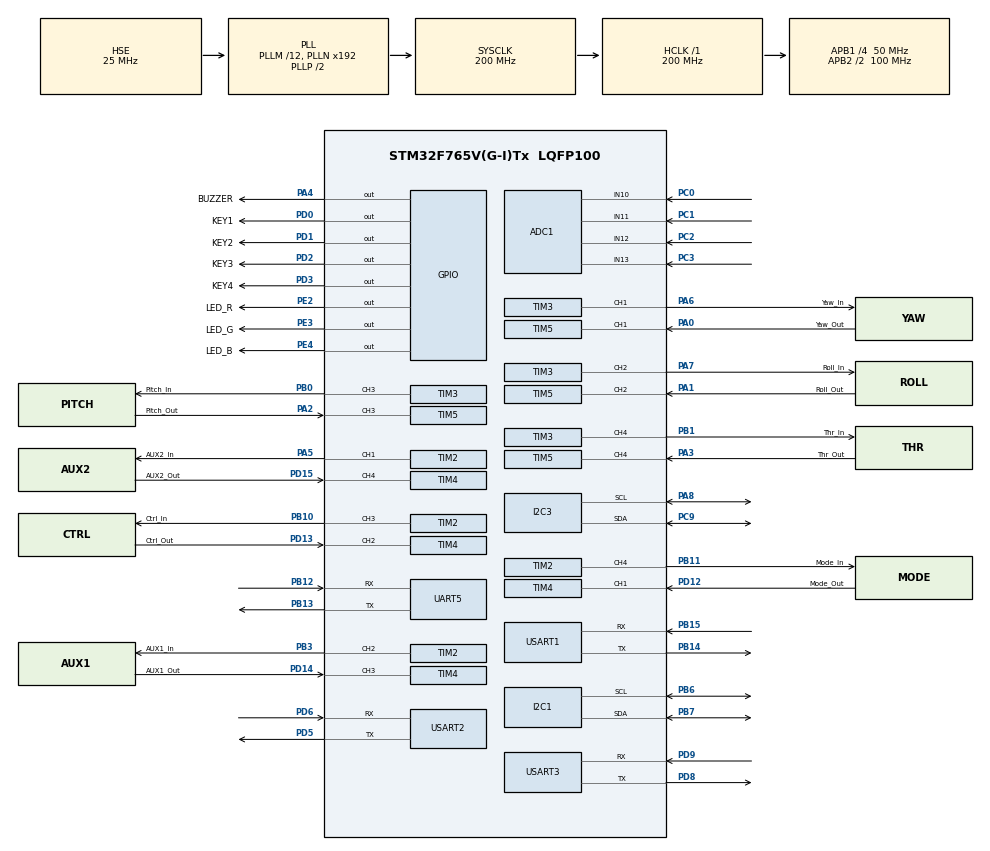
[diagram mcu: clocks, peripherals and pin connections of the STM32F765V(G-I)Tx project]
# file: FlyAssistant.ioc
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ADC1.Channel-1\#ChannelRegularConversion=ADC_CHANNEL_10
ADC1.NbrOfConversionFlag=1
ADC1.Rank-1\#ChannelRegularConversion=1
ADC1.SamplingTime-1\#ChannelRegularConversion=ADC_SAMPLETIME_3CYCLES
ADC1.master=1
CORTEX_M7.default_mode_Activation=1
I2C1.Timing=0x00C0EAFF
I2C3.Timing=0x00C0EAFF
Mcu.Family=STM32F7
Mcu.Name=STM32F765V(G-I)Tx
Mcu.Package=LQFP100
NVIC.PriorityGroup=NVIC_PRIORITYGROUP_4
NVIC.TIM2_IRQn=true\:0\:0\:false\:false\:true\:true\:true\:true
NVIC.TIM3_IRQn=true\:0\:0\:false\:false\:true\:true\:true\:true
NVIC.TIM4_IRQn=true\:0\:0\:false\:false\:true\:true\:true\:true
NVIC.TIM5_IRQn=true\:0\:0\:false\:false\:true\:true\:true\:true
NVIC.UART5_IRQn=true\:0\:0\:false\:false\:true\:true\:true\:true
NVIC.USART1_IRQn=true\:0\:0\:false\:false\:true\:true\:true\:true
NVIC.USART2_IRQn=true\:0\:0\:false\:false\:true\:true\:true\:true
NVIC.USART3_IRQn=true\:0\:0\:false\:false\:true\:true\:true\:true
PA0/WKUP.GPIO_Label=Yaw_Out
PA0/WKUP.Signal=S_TIM5_CH1
PA1.GPIO_Label=Roll_Out
PA1.Signal=S_TIM5_CH2
PA13.Mode=Serial_Wire
PA13.Signal=SYS_JTMS-SWDIO
PA14.Mode=Serial_Wire
PA14.Signal=SYS_JTCK-SWCLK
PA2.GPIO_Label=Pitch_Out
PA2.Signal=S_TIM5_CH3
PA3.GPIO_Label=Thr_Out
PA3.Signal=S_TIM5_CH4
PA4.GPIO_Label=BUZZER
PA4.Signal=GPIO_Output
PA5.GPIO_Label=AUX2_In
PA5.Signal=S_TIM2_CH1_ETR
PA6.GPIO_Label=Yaw_In
PA6.Signal=S_TIM3_CH1
PA7.GPIO_Label=Roll_In
PA7.Signal=S_TIM3_CH2
PA8.Mode=I2C
PA8.Signal=I2C3_SCL
PB0.GPIO_Label=Pitch_In
PB0.Signal=S_TIM3_CH3
PB1.GPIO_Label=Thr_In
PB1.Signal=S_TIM3_CH4
PB10.GPIO_Label=Ctrl_In
PB10.Signal=S_TIM2_CH3
PB11.GPIO_Label=Mode_In
PB11.Signal=S_TIM2_CH4
PB12.Mode=Asynchronous
PB12.Signal=UART5_RX
PB13.Mode=Asynchronous
PB13.Signal=UART5_TX
PB14.Mode=Asynchronous
PB14.Signal=USART1_TX
PB15.Mode=Asynchronous
PB15.Signal=USART1_RX
PB3.GPIO_Label=AUX1_In
PB3.Signal=S_TIM2_CH2
PB6.Mode=I2C
PB6.Signal=I2C1_SCL
PB7.Mode=I2C
PB7.Signal=I2C1_SDA
PC0.Signal=ADCx_IN10
PC1.Signal=ADCx_IN11
PC2.Signal=ADCx_IN12
PC3.Signal=ADCx_IN13
PC9.Mode=I2C
PC9.Signal=I2C3_SDA
PD0.GPIO_Label=KEY1
PD0.Signal=GPIO_Output
PD1.GPIO_Label=KEY2
PD1.Signal=GPIO_Output
PD12.GPIO_Label=Mode_Out
PD12.Signal=S_TIM4_CH1
PD13.GPIO_Label=Ctrl_Out
PD13.Signal=S_TIM4_CH2
PD14.GPIO_Label=AUX1_Out
PD14.Signal=S_TIM4_CH3
PD15.GPIO_Label=AUX2_Out
PD15.Signal=S_TIM4_CH4
PD2.GPIO_Label=KEY3
PD2.Signal=GPIO_Output
PD3.GPIO_Label=KEY4
PD3.Signal=GPIO_Output
PD5.Mode=Asynchronous
PD5.Signal=USART2_TX
PD6.Mode=Asynchronous
PD6.Signal=USART2_RX
PD8.Mode=Asynchronous
PD8.Signal=USART3_TX
PD9.Mode=Asynchronous
PD9.Signal=USART3_RX
PE2.GPIO_Label=LED_R
PE2.Signal=GPIO_Output
PE3.GPIO_Label=LED_G
PE3.Signal=GPIO_Output
PE4.GPIO_Label=LED_B
PE4.Signal=GPIO_Output
PH0/OSC_IN.Mode=HSE-External-Oscillator
PH0/OSC_IN.Signal=RCC_OSC_IN
PH1/OSC_OUT.Mode=HSE-External-Oscillator
PH1/OSC_OUT.Signal=RCC_OSC_OUT
ProjectManager.HeapSize=0x200
ProjectManager.StackSize=0x400
ProjectManager.TargetToolchain=MDK-ARM V5
RCC.AHBFreq_Value=200000000
RCC.APB1CLKDivider=RCC_HCLK_DIV4
RCC.APB1Freq_Value=50000000
RCC.APB1TimFreq_Value=100000000
RCC.APB2CLKDivider=RCC_HCLK_DIV2
RCC.APB2Freq_Value=100000000
RCC.APB2TimFreq_Value=200000000
RCC.CortexFreq_Value=200000000
RCC.HCLKFreq_Value=200000000
RCC.HSE_VALUE=25000000
RCC.HSI_VALUE=16000000
RCC.LSE_VALUE=32768
RCC.PLLM=12
RCC.PLLSourceVirtual=RCC_PLLSOURCE_HSE
RCC.SYSCLKFreq_VALUE=200000000
RCC.SYSCLKSource=RCC_SYSCLKSOURCE_PLLCLK
RCC.USBFreq_Value=200000000
RCC.VCOOutputFreq_Value=400000000
SH.ADCx_IN10.0=ADC1_IN10,IN10
SH.ADCx_IN11.0=ADC1_IN11,IN11
SH.ADCx_IN12.0=ADC1_IN12,IN12
SH.ADCx_IN13.0=ADC1_IN13,IN13
SH.S_TIM2_CH1_ETR.0=TIM2_CH1,PWM Generation1 CH1
SH.S_TIM2_CH2.0=TIM2_CH2,PWM Generation2 CH2
SH.S_TIM2_CH3.0=TIM2_CH3,PWM Generation3 CH3
SH.S_TIM2_CH4.0=TIM2_CH4,PWM Generation4 CH4
SH.S_TIM3_CH1.0=TIM3_CH1,PWM Generation1 CH1
SH.S_TIM3_CH2.0=TIM3_CH2,PWM Generation2 CH2
SH.S_TIM3_CH3.0=TIM3_CH3,PWM Generation3 CH3
SH.S_TIM3_CH4.0=TIM3_CH4,PWM Generation4 CH4
SH.S_TIM4_CH1.0=TIM4_CH1,Input_Capture1_from_TI1
SH.S_TIM4_CH2.0=TIM4_CH2,Input_Capture2_from_TI2
SH.S_TIM4_CH3.0=TIM4_CH3,Input_Capture3_from_TI3
SH.S_TIM4_CH4.0=TIM4_CH4,Input_Capture4_from_TI4
SH.S_TIM5_CH1.0=TIM5_CH1,Input_Capture1_from_TI1
SH.S_TIM5_CH2.0=TIM5_CH2,Input_Capture2_from_TI2
SH.S_TIM5_CH3.0=TIM5_CH3,Input_Capture3_from_TI3
SH.S_TIM5_CH4.0=TIM5_CH4,Input_Capture4_from_TI4
TIM2.Channel-PWM\ Generation1\ CH1=TIM_CHANNEL_1
TIM2.Channel-PWM\ Generation2\ CH2=TIM_CHANNEL_2
TIM2.Channel-PWM\ Generation3\ CH3=TIM_CHANNEL_3
TIM2.Channel-PWM\ Generation4\ CH4=TIM_CHANNEL_4
TIM2.Period=60000
TIM2.Prescaler=33
TIM3.Channel-PWM\ Generation1\ CH1=TIM_CHANNEL_1
TIM3.Channel-PWM\ Generation2\ CH2=TIM_CHANNEL_2
TIM3.Channel-PWM\ Generation3\ CH3=TIM_CHANNEL_3
TIM3.Channel-PWM\ Generation4\ CH4=TIM_CHANNEL_4
TIM3.Period=60000
TIM3.Prescaler=33
TIM4.Channel-Input_Capture1_from_TI1=TIM_CHANNEL_1
TIM4.Channel-Input_Capture2_from_TI2=TIM_CHANNEL_2
TIM4.Channel-Input_Capture3_from_TI3=TIM_CHANNEL_3
TIM4.Channel-Input_Capture4_from_TI4=TIM_CHANNEL_4
TIM4.Period=60000
TIM4.Prescaler=33
TIM5.Channel-Input_Capture1_from_TI1=TIM_CHANNEL_1
TIM5.Channel-Input_Capture2_from_TI2=TIM_CHANNEL_2
TIM5.Channel-Input_Capture3_from_TI3=TIM_CHANNEL_3
TIM5.Channel-Input_Capture4_from_TI4=TIM_CHANNEL_4
TIM5.Period=60000
TIM5.Prescaler=33
USART1.VirtualMode-Asynchronous=VM_ASYNC
USART2.VirtualMode-Asynchronous=VM_ASYNC
USART3.VirtualMode-Asynchronous=VM_ASYNC
VP_TIM2_VS_ClockSourceINT.Mode=Internal
VP_TIM3_VS_ClockSourceINT.Mode=Internal
board=custom

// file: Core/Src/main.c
/* USER CODE BEGIN Header */
/**
  ******************************************************************************
  * @file           : main.c
  * @brief          : Main program body
  ******************************************************************************
  * @attention
  *
  * Copyright (c) 2022 STMicroelectronics.
  * All rights reserved.
  *
  * This software is licensed under terms that can be found in the LICENSE file
  * in the root directory of this software component.
  * If no LICENSE file comes with this software, it is provided AS-IS.
  *
  ******************************************************************************
  */
/* USER CODE END Header */
#include "main.h"

/* USER CODE BEGIN Includes */
#include "stdio.h"
#include "math.h"
#include "arm_math.h"
#include <stdarg.h>
#include <string.h>
#include "mavlink.h"
#include "mavlink_types.h"

#include "led.h"
#include "key.h"
#include "uart_api.h"
#include "beep.h"
#include "coderDecoder.h"
#include "flyControl.h"
#include "MAV_Altitude_Decode.h"

/* 定义例程名和例程发布日期 */
#define EXAMPLE_NAME	"V4梦创飞控室内自动飞行例程"
#define EXAMPLE_DATE	"2021-04-7 "
#define DEMO_VER		  "V-1.0"

#define Flag_SendToUsart  1

#define CH_NUM	1	/* 8通道 */
#define N 3
#define  voltage_ratio   204  //2.04

#define USART1_MAX_RECV_LEN		256				//最大接收缓存字节数
#define USART2_MAX_RECV_LEN		256
#define USART3_MAX_RECV_LEN		256
#define BUFFSIZE 5

int CHANNEL_1_RISE=0,CHANNEL_1_FALL=0,CHANNEL_1_PULSE_WIDE=0;
int CHANNEL_2_RISE=0,CHANNEL_2_FALL=0,CHANNEL_2_PULSE_WIDE=0;
int CHANNEL_3_RISE=0,CHANNEL_3_FALL=0,CHANNEL_3_PULSE_WIDE=0;
int CHANNEL_4_RISE=0,CHANNEL_4_FALL=0,CHANNEL_4_PULSE_WIDE=0;
int CHANNEL_5_RISE=0,CHANNEL_5_FALL=0,CHANNEL_5_PULSE_WIDE=0;
int CHANNEL_6_RISE=0,CHANNEL_6_FALL=0,CHANNEL_6_PULSE_WIDE=0;
int CHANNEL_7_RISE=0,CHANNEL_7_FALL=0,CHANNEL_7_PULSE_WIDE=0;
int CHANNEL_8_RISE=0,CHANNEL_8_FALL=0,CHANNEL_8_PULSE_WIDE=0;

int ICFLAG_1 = 1,ICFLAG_2 = 1,ICFLAG_3 = 1, ICFLAG_4 = 1, ICFLAG_5 = 1, ICFLAG_6 = 1, ICFLAG_7 = 1, ICFLAG_8 = 1;

 int PWM_Mode_N1 =3000;
 int PWM_Mode_N2 =4000;
 int PWM_Mode_N3 =5000;
 int PWM_Mode_N4 =6000;

uint16_t    USART1_RX_STA=0;
uint16_t    USART2_RX_STA=0;
uint16_t    USART3_RX_STA=0;
static int Recv_Cnt_UART1 = 0;
static int Recv_Cnt_UART2 = 0;
static int Recv_Cnt_UART3 = 0;
static int UART1_Frame_Flag = 0;
static int UART2_Frame_Flag = 0;
static int UART3_Frame_Flag = 0;
static int heartbeat = 0;
static int MAVLink_message_length = 0;
static mavlink_distance_sensor_t packet;
static float height = 0;

uint8_t USART1_RX_BUF [USART1_MAX_RECV_LEN];
uint8_t USART2_RX_BUF [USART2_MAX_RECV_LEN];
uint8_t USART3_RX_BUF [USART3_MAX_RECV_LEN];
uint8_t FreeBuffer_Encode [USART2_MAX_RECV_LEN];
uint8_t FreeBuffer_Encode_3[USART3_MAX_RECV_LEN];
uint8_t MAVLink_RECV_BUF[USART2_MAX_RECV_LEN];
uint8_t MAVLink_TX_BUF [MAVLINK_MAX_PACKET_LEN];
uint8_t MAVLink_RECV_BUF_FAKE [USART2_MAX_RECV_LEN] = {0};

//回应 头 消息号 数据1  数据2 数据3 数据4 尾
uint8_t encodeAnswer[11]    ={'#','1',0x00,0x00,0x00,0x00,0x00,0x00,0x00,0x00,'*'};

#define A 60
float old_value;

static      int16_t s_dat[CH_NUM];
float       s_volt[CH_NUM];

uint32_t    ADC_ReadBuffer[CH_NUM];
float  OutData_Test[4];
float  OutData[4];
char   menu=0;

PID         PID_Control_Att;           //  PID Control Structure
float filter(float new_value);

void  OutPut_Data(void);
float ADC_CvtVolt(void);
float DataProcessing(float IN_Data);
float ADC_CvtVolt_and_filter(void);
float get_adc(char adc_id);
float filter_av(char filter_id);
void TIM3_Set(uint8_t sta);
void TIM2_Set(uint8_t sta);
void TIM5_Set(uint8_t sta);
void Data_to_VisualScope(void);
unsigned short CRC_CHECK(unsigned char *Buf, unsigned char CRC_CNT);

//mavlink
void MANUAL_CONTROL_Send(int16_t xpoint,int16_t ypoint);
void RC_CHANNELS_OVERRIDE_Send(int16_t xpoint,int16_t ypoint);
void heartbeat_Mavlink(void);
int  RC_Read(void);
void Back_to_Center(void);

void end(void)
{
	printf("%c",0xff);
	printf("%c",0xff);
	printf("%c",0xff);
}

/* 仅允许本文件内调用的函数声明 */
static void PrintfLogo(void);
static void PrintfHardInfo(void);

/* USER CODE END Includes */

 ADC_HandleTypeDef hadc1;

I2C_HandleTypeDef hi2c1;
I2C_HandleTypeDef hi2c3;

TIM_HandleTypeDef htim2;
TIM_HandleTypeDef htim3;
TIM_HandleTypeDef htim4;
TIM_HandleTypeDef htim5;

void SystemClock_Config(void);
static void MPU_Config(void);
static void MX_GPIO_Init(void);
static void MX_ADC1_Init(void);
static void MX_I2C1_Init(void);
static void MX_I2C3_Init(void);
static void MX_TIM2_Init(void);
static void MX_TIM3_Init(void);
static void MX_TIM4_Init(void);
static void MX_TIM5_Init(void);
static void MX_UART5_Init(void);
static void MX_USART1_UART_Init(void);
static void MX_USART2_UART_Init(void);
static void MX_USART3_UART_Init(void);
/* USER CODE BEGIN PFP */
////////////////////////////////不懂刚干啥用的
#ifdef __GNUC__
/* With GCC/RAISONANCE, small printf (option LD Linker->Libraries->Small printf
	 set to 'Yes') calls __io_putchar() */
#define PUTCHAR_PROTOTYPE int __io_putchar(int ch)
#else
#define PUTCHAR_PROTOTYPE int fputc(int ch, FILE *f)
#endif /* __GNUC__ */

PUTCHAR_PROTOTYPE
{
    BSP_USART_SendData_LL( USART1, ch);
	  return ch;
}
/* USER CODE END PFP */

int main(void)
{
  /* USER CODE BEGIN 1 */
	uint16_t i1=0,i2=0,i3=0;
	uint16_t rxlen_usart_1;
	uint16_t rxlen_usart_2;
  uint16_t rxlen_usart_3;
	uint8_t cmd=0;
	uint8_t key;
	uint32_t RunTime=0;
	uint32_t decodetimer;
	uint32_t tickstart = HAL_GetTick();
	uint32_t ticklast = HAL_GetTick();
	mavlink_message_t msg1;
	mavlink_message_t msg2;
	mavlink_message_t msg_tmp;
	mavlink_message_t msg_altitude;
	mavlink_message_t msg_request_data_stream;
	uint32_t len = 0;
  /* USER CODE END 1 */

  /* MPU Configuration--------------------------------------------------------*/
  MPU_Config();

  /* MCU Configuration--------------------------------------------------------*/

  /* Reset of all peripherals, Initializes the Flash interface and the Systick. */
  HAL_Init();

  /* Configure the system clock */
  SystemClock_Config();

  /* Initialize all configured peripherals */
  MX_GPIO_Init();
  MX_ADC1_Init();
  MX_I2C1_Init();
  MX_I2C3_Init();
  MX_TIM2_Init();
  MX_TIM3_Init();
  MX_TIM4_Init();
  MX_TIM5_Init();
  MX_UART5_Init();
  MX_USART1_UART_Init();
  MX_USART2_UART_Init();
  MX_USART3_UART_Init();
  /* USER CODE BEGIN 2 */
	Device_Init();
	PrintfLogo();		  /* 打印例程Logo到串口1 */
	PrintfHardInfo();	/* 打印硬件接线信息 */

	/*
		由于ST固件库的启动文件已经执行了CPU系统时钟的初始化，所以不必再次重复配置系统时钟。
		启动文件配置了CPU主时钟频率、内部Flash访问速度和可选的外部SRAM FSMC初始化。
	*/

		//HAL_ADC_Init(&hadc1);
		//HAL_ADC_Start(&hadc1);

		//开启PWM
		HAL_TIM_PWM_Init(&htim2);
		HAL_TIM_PWM_Start(&htim2, TIM_CHANNEL_1);
		HAL_TIM_PWM_Start(&htim2, TIM_CHANNEL_2);
		HAL_TIM_PWM_Start(&htim2, TIM_CHANNEL_3);
		HAL_TIM_PWM_Start(&htim2, TIM_CHANNEL_4);

		HAL_TIM_PWM_Init(&htim3);
		HAL_TIM_PWM_Start(&htim3, TIM_CHANNEL_1);
		HAL_TIM_PWM_Start(&htim3, TIM_CHANNEL_2);
		HAL_TIM_PWM_Start(&htim3, TIM_CHANNEL_3);
		HAL_TIM_PWM_Start(&htim3, TIM_CHANNEL_4);

		/// 使能定时器输入捕获。
		HAL_TIM_IC_Start_IT(&htim4,TIM_CHANNEL_1);
		HAL_TIM_IC_Start_IT(&htim4,TIM_CHANNEL_2);
		HAL_TIM_IC_Start_IT(&htim4,TIM_CHANNEL_3);
		HAL_TIM_IC_Start_IT(&htim4,TIM_CHANNEL_4);

		HAL_TIM_IC_Start_IT(&htim5,TIM_CHANNEL_1);
		HAL_TIM_IC_Start_IT(&htim5,TIM_CHANNEL_2);
		HAL_TIM_IC_Start_IT(&htim5,TIM_CHANNEL_3);
		HAL_TIM_IC_Start_IT(&htim5,TIM_CHANNEL_4);

		PIDInit(&PID_Control_Att);
		LED1_Flash();
		BEEP_ON();
		HAL_Delay(1000);
		BEEP_OFF();
		HAL_Delay(1000);

		BSP_USART_StartIT_LL( USART1 );
	  BSP_USART_StartIT_LL( USART2 );
    BSP_USART_StartIT_LL( USART3 );

	  USART1_RX_STA=0;		//清零
	  USART2_RX_STA=0;		//清零

		TIM3_Set(0);
	  TIM5_Set(0);

///*************************************打一个假包，用于获取消息实际长度*************/
//		mavlink_msg_altitude_pack(54,0,&msg_tmp,0,1,1,1,1,1,1);                       //
//	  MAVLink_message_length=mavlink_msg_to_send_buffer(MAVLink_TX_BUF,&msg_tmp);   //
///**********************************************************************************/

		mavlink_msg_request_data_stream_pack(54,0,&msg_request_data_stream,0,0,12,5,1);
		len = mavlink_msg_to_send_buffer(MAVLink_TX_BUF, &msg_request_data_stream);
    BSP_USART_SendArray_LL(USART3, MAVLink_TX_BUF, len);
		BSP_USART_SendArray_LL(USART2, MAVLink_TX_BUF, len);
		BSP_USART_SendArray_LL(USART1, MAVLink_TX_BUF, len);
  /* USER CODE END 2 */

  /* Infinite loop */
  while (1)
  {

    /* USER CODE BEGIN 3 */
		//		BSP_USART_SendArray_LL(USART1, MAVLink_TX_BUF, len);
		//LED_G_Flash();
		//mavlink读取飞控
		key=KeyScanning(0);            //按键扫描
		switch(key)
		{
			case  KEY1_PRES:	//控制LED0,LED1互斥点亮
						LED_B_Flash();
						BEEP_ON();
			      Unlock();
						break;
			case  KEY2_PRES:	//控制LED0翻转
						LED_G_Flash();
						BEEP_OFF();
						break;
		}
		if(InitedFlag)  //确保设备已初始化
		{
			/********************************UART1接收并处理数据**********************************/
			 if(USART1_RX_STA & 0X8000)		  //接收到一次数据了
			 {
        //printf("USART1 INT =%d \r\n",USART1_RX_STA);
				rxlen_usart_1 = USART1_RX_STA & 0x7FFF;	//得到数据长度
				//printf("This is a USART1 test rxlen_usart_1 = %d USART1_RX_STA= %d\r\n" ,rxlen_usart_1 ,USART1_RX_STA);
				for(i1=0;i1<rxlen_usart_1;i1++)
				{
					FreeBuffer_Encode[i1]=USART1_RX_BUF[i1];	 //将串口2接收到的数据传输给自由缓冲区
					//BSP_USART_SendArray_LL( USART1,&FreeBuffer_Encode[i1],1);
				}
				cmd=encodeDecode_Analysis(FreeBuffer_Encode,encodeAnswer,rxlen_usart_1); //分析字符串
				BSP_USART_StartIT_LL( USART1 );
				rxlen_usart_1=0;
				USART1_RX_STA=0;	 //启动下一次接收
			}
			/********************************UART2接收并处理数据***********************************/
			if(USART2_RX_STA & 0X8000)		  //接收到一次数据，且超过了预设长度
			 {
				rxlen_usart_2 = USART2_RX_STA & 0x7FFF;	//得到数据长度
				//printf("This is a USART1 test rxlen_usart_1 = %d USART1_RX_STA= %d\r\n" ,rxlen_usart_1 ,USART1_RX_STA);
				for(i2=0;i2<rxlen_usart_2;i2++)
				{
					MAVLink_RECV_BUF[i2]=USART2_RX_BUF[i2];						//将串口2接收到的数据传输给自由缓冲区
				}
//				Mav_Altitude_Decoder(rxlen_usart_2, msg_altitude, MAVLink_RECV_BUF, &height);
				// if(Mav_Altitude_Decoder(rxlen_usart_2, msg_altitude, MAVLink_RECV_BUF, &height)==1) //分析字符串
				// {
				// 	printf("\r\nheight = %f \r\n", height);
				// }
				//BSP_USART_SendArray_LL(USART1, MAVLink_RECV_BUF, rxlen_usart_2);
//				//printf("rxlen_usart_2 = %d\r\n", rxlen_usart_2);
				rxlen_usart_2=0;
				USART2_RX_STA=0;
				BSP_USART_StartIT_LL( USART2 ); //启动下一次接收
				}
        /*****************************USART3接收&处理数据***********************************/
        if(USART3_RX_STA & 0x8000)    //接收满一次数据
        {
          rxlen_usart_3 = USART3_RX_STA & 0x7FFF;   //得到数据长度
          for(i3=0;i3<rxlen_usart_3;i3++)
          {
            FreeBuffer_Encode_3[i3] = USART3_RX_BUF[i3];    //将串口3接收的数据传输到自由缓冲区
          }
          //解码处理...->待写；注意多个设备向飞控助手串口发送时，飞控助手如何全部处理
          //cmd=encodeDecode_Analysis(FreeBuffer_Encode_3,encodeAnswer,rxlen_usart_1); //分析字符串
          rxlen_usart_3 = 0;
          USART3_RX_STA = 0;
          BSP_USART_StartIT_LL( USART3 );   //启动下一次接收
        }

				//执行指令的当作
				if(2==RC_Read())//读取是否直通
				{
					 Set_PWM_Mode(4500);
					 switch (cmd)
					 {
							case 1:   //悬停->前往目标点
								printf("loiter  \r\n");
								Loiter(Attitude.Position_x,Attitude.Position_y,Attitude.SetPoint_x,Attitude.SetPoint_y);
							  //RC_bridge_Test();
								heartbeat = 0;
								break;
							case 2:   //向右飞
								printf("right \r\n");
							  Go_right(4500+10);
							  //RC_bridge_Test();
								heartbeat = 0;
								break;
							case 3:   //向左飞
								printf("left \r\n");
							  Go_left(4500+10);
							  //RC_bridge_Test();
								heartbeat = 0;
								break;
              case 4:   //向前飞
                printf("ahead \r\n");
                Go_ahead(4500+10);
                heartbeat = 0;
                break;
              case 5:   //向后飞
                printf("back \r\n");
                Go_back(4500+10);
                heartbeat = 0;
                break;
							default:  //各通道回中
								printf("default\r\n");
								Back_to_Center();//没有UART数据输入时各通道回中
							  break;
					 }
					 heartbeat++;
					 if(heartbeat>3000)
					 {
						 cmd =0;
						 heartbeat = 0;
					 }
				 }
				 else if(3==RC_Read())
				 {
					 //桥接模式
					 RC_bridge();
				 }
				 else if(1==RC_Read())
				 {
					 Set_PWM_Mode(6000);
					 Set_PWM_Thr(4500);
					 Set_PWM_Pitch(4500);
					 Set_PWM_Roll(4500);
					 Set_PWM_Yaw(4500);

				 }
				 //LED_G_Flash();
				 RC_bridge_Test();
		}
		//指示灯
		RunTime = HAL_GetTick() - tickstart;
		if(RunTime>1000)
		{
			//printf("RunTime>1000%d \r\n",RunTime);
			tickstart = HAL_GetTick();
			LED_G_Flash();
			HAL_Delay(10);
			LED_R_Flash();
			HAL_Delay(20);
			LED_B_Flash();
		}
  }
  /* USER CODE END 3 */
}

void SystemClock_Config(void)
{
  RCC_OscInitTypeDef RCC_OscInitStruct = {0};
  RCC_ClkInitTypeDef RCC_ClkInitStruct = {0};

  /** Configure the main internal regulator output voltage
  */
  __HAL_RCC_PWR_CLK_ENABLE();
  __HAL_PWR_VOLTAGESCALING_CONFIG(PWR_REGULATOR_VOLTAGE_SCALE1);

  /** Initializes the RCC Oscillators according to the specified parameters
  * in the RCC_OscInitTypeDef structure.
  */
  RCC_OscInitStruct.OscillatorType = RCC_OSCILLATORTYPE_LSI|RCC_OSCILLATORTYPE_HSE;
  RCC_OscInitStruct.HSEState = RCC_HSE_ON;
  RCC_OscInitStruct.LSIState = RCC_LSI_ON;
  RCC_OscInitStruct.PLL.PLLState = RCC_PLL_ON;
  RCC_OscInitStruct.PLL.PLLSource = RCC_PLLSOURCE_HSE;
  RCC_OscInitStruct.PLL.PLLM = 12;
  RCC_OscInitStruct.PLL.PLLN = 192;
  RCC_OscInitStruct.PLL.PLLP = RCC_PLLP_DIV2;
  RCC_OscInitStruct.PLL.PLLQ = 2;
  RCC_OscInitStruct.PLL.PLLR = 2;
  if (HAL_RCC_OscConfig(&RCC_OscInitStruct) != HAL_OK)
  {
    Error_Handler();
  }

  /** Activate the Over-Drive mode
  */
  if (HAL_PWREx_EnableOverDrive() != HAL_OK)
  {
    Error_Handler();
  }

  /** Initializes the CPU, AHB and APB buses clocks
  */
  RCC_ClkInitStruct.ClockType = RCC_CLOCKTYPE_HCLK|RCC_CLOCKTYPE_SYSCLK
                              |RCC_CLOCKTYPE_PCLK1|RCC_CLOCKTYPE_PCLK2;
  RCC_ClkInitStruct.SYSCLKSource = RCC_SYSCLKSOURCE_PLLCLK;
  RCC_ClkInitStruct.AHBCLKDivider = RCC_SYSCLK_DIV1;
  RCC_ClkInitStruct.APB1CLKDivider = RCC_HCLK_DIV4;
  RCC_ClkInitStruct.APB2CLKDivider = RCC_HCLK_DIV2;

  if (HAL_RCC_ClockConfig(&RCC_ClkInitStruct, FLASH_LATENCY_6) != HAL_OK)
  {
    Error_Handler();
  }
}

static void MX_ADC1_Init(void)
{

  ADC_ChannelConfTypeDef sConfig = {0};

  /** Configure the global features of the ADC (Clock, Resolution, Data Alignment and number of conversion)
  */
  hadc1.Instance = ADC1;
  hadc1.Init.ClockPrescaler = ADC_CLOCK_SYNC_PCLK_DIV4;
  hadc1.Init.Resolution = ADC_RESOLUTION_12B;
  hadc1.Init.ScanConvMode = ADC_SCAN_DISABLE;
  hadc1.Init.ContinuousConvMode = DISABLE;
  hadc1.Init.DiscontinuousConvMode = DISABLE;
  hadc1.Init.ExternalTrigConvEdge = ADC_EXTERNALTRIGCONVEDGE_NONE;
  hadc1.Init.ExternalTrigConv = ADC_SOFTWARE_START;
  hadc1.Init.DataAlign = ADC_DATAALIGN_RIGHT;
  hadc1.Init.NbrOfConversion = 1;
  hadc1.Init.DMAContinuousRequests = DISABLE;
  hadc1.Init.EOCSelection = ADC_EOC_SINGLE_CONV;
  if (HAL_ADC_Init(&hadc1) != HAL_OK)
  {
    Error_Handler();
  }

  /** Configure for the selected ADC regular channel its corresponding rank in the sequencer and its sample time.
  */
  sConfig.Channel = ADC_CHANNEL_10;
  sConfig.Rank = ADC_REGULAR_RANK_1;
  sConfig.SamplingTime = ADC_SAMPLETIME_3CYCLES;
  if (HAL_ADC_ConfigChannel(&hadc1, &sConfig) != HAL_OK)
  {
    Error_Handler();
  }

}

static void MX_I2C1_Init(void)
{

  hi2c1.Instance = I2C1;
  hi2c1.Init.Timing = 0x00C0EAFF;
  hi2c1.Init.OwnAddress1 = 0;
  hi2c1.Init.AddressingMode = I2C_ADDRESSINGMODE_7BIT;
  hi2c1.Init.DualAddressMode = I2C_DUALADDRESS_DISABLE;
  hi2c1.Init.OwnAddress2 = 0;
  hi2c1.Init.OwnAddress2Masks = I2C_OA2_NOMASK;
  hi2c1.Init.GeneralCallMode = I2C_GENERALCALL_DISABLE;
  hi2c1.Init.NoStretchMode = I2C_NOSTRETCH_DISABLE;
  if (HAL_I2C_Init(&hi2c1) != HAL_OK)
  {
    Error_Handler();
  }

  /** Configure Analogue filter
  */
  if (HAL_I2CEx_ConfigAnalogFilter(&hi2c1, I2C_ANALOGFILTER_ENABLE) != HAL_OK)
  {
    Error_Handler();
  }

  /** Configure Digital filter
  */
  if (HAL_I2CEx_ConfigDigitalFilter(&hi2c1, 0) != HAL_OK)
  {
    Error_Handler();
  }

}

static void MX_I2C3_Init(void)
{

  hi2c3.Instance = I2C3;
  hi2c3.Init.Timing = 0x00C0EAFF;
  hi2c3.Init.OwnAddress1 = 0;
  hi2c3.Init.AddressingMode = I2C_ADDRESSINGMODE_7BIT;
  hi2c3.Init.DualAddressMode = I2C_DUALADDRESS_DISABLE;
  hi2c3.Init.OwnAddress2 = 0;
  hi2c3.Init.OwnAddress2Masks = I2C_OA2_NOMASK;
  hi2c3.Init.GeneralCallMode = I2C_GENERALCALL_DISABLE;
  hi2c3.Init.NoStretchMode = I2C_NOSTRETCH_DISABLE;
  if (HAL_I2C_Init(&hi2c3) != HAL_OK)
  {
    Error_Handler();
  }

  /** Configure Analogue filter
  */
  if (HAL_I2CEx_ConfigAnalogFilter(&hi2c3, I2C_ANALOGFILTER_ENABLE) != HAL_OK)
  {
    Error_Handler();
  }

  /** Configure Digital filter
  */
  if (HAL_I2CEx_ConfigDigitalFilter(&hi2c3, 0) != HAL_OK)
  {
    Error_Handler();
  }

}

static void MX_TIM2_Init(void)
{

  TIM_ClockConfigTypeDef sClockSourceConfig = {0};
  TIM_MasterConfigTypeDef sMasterConfig = {0};
  TIM_OC_InitTypeDef sConfigOC = {0};

  htim2.Instance = TIM2;
  htim2.Init.Prescaler = 33;
  htim2.Init.CounterMode = TIM_COUNTERMODE_UP;
  htim2.Init.Period = 60000;
  htim2.Init.ClockDivision = TIM_CLOCKDIVISION_DIV1;
  htim2.Init.AutoReloadPreload = TIM_AUTORELOAD_PRELOAD_DISABLE;
  if (HAL_TIM_Base_Init(&htim2) != HAL_OK)
  {
    Error_Handler();
  }
  sClockSourceConfig.ClockSource = TIM_CLOCKSOURCE_INTERNAL;
  if (HAL_TIM_ConfigClockSource(&htim2, &sClockSourceConfig) != HAL_OK)
  {
    Error_Handler();
  }
  if (HAL_TIM_PWM_Init(&htim2) != HAL_OK)
  {
    Error_Handler();
  }
  sMasterConfig.MasterOutputTrigger = TIM_TRGO_RESET;
  sMasterConfig.MasterSlaveMode = TIM_MASTERSLAVEMODE_DISABLE;
  if (HAL_TIMEx_MasterConfigSynchronization(&htim2, &sMasterConfig) != HAL_OK)
  {
    Error_Handler();
  }
  sConfigOC.OCMode = TIM_OCMODE_PWM1;
  sConfigOC.Pulse = 0;
  sConfigOC.OCPolarity = TIM_OCPOLARITY_HIGH;
  sConfigOC.OCFastMode = TIM_OCFAST_DISABLE;
  if (HAL_TIM_PWM_ConfigChannel(&htim2, &sConfigOC, TIM_CHANNEL_1) != HAL_OK)
  {
    Error_Handler();
  }
  if (HAL_TIM_PWM_ConfigChannel(&htim2, &sConfigOC, TIM_CHANNEL_2) != HAL_OK)
  {
    Error_Handler();
  }
  if (HAL_TIM_PWM_ConfigChannel(&htim2, &sConfigOC, TIM_CHANNEL_3) != HAL_OK)
  {
    Error_Handler();
  }
  if (HAL_TIM_PWM_ConfigChannel(&htim2, &sConfigOC, TIM_CHANNEL_4) != HAL_OK)
  {
    Error_Handler();
  }
  HAL_TIM_MspPostInit(&htim2);

}

static void MX_TIM3_Init(void)
{

  TIM_ClockConfigTypeDef sClockSourceConfig = {0};
  TIM_MasterConfigTypeDef sMasterConfig = {0};
  TIM_OC_InitTypeDef sConfigOC = {0};

  htim3.Instance = TIM3;
  htim3.Init.Prescaler = 33;
  htim3.Init.CounterMode = TIM_COUNTERMODE_UP;
  htim3.Init.Period = 60000;
  htim3.Init.ClockDivision = TIM_CLOCKDIVISION_DIV1;
  htim3.Init.AutoReloadPreload = TIM_AUTORELOAD_PRELOAD_DISABLE;
  if (HAL_TIM_Base_Init(&htim3) != HAL_OK)
  {
    Error_Handler();
  }
  sClockSourceConfig.ClockSource = TIM_CLOCKSOURCE_INTERNAL;
  if (HAL_TIM_ConfigClockSource(&htim3, &sClockSourceConfig) != HAL_OK)
  {
    Error_Handler();
  }
  if (HAL_TIM_PWM_Init(&htim3) != HAL_OK)
  {
    Error_Handler();
  }
  sMasterConfig.MasterOutputTrigger = TIM_TRGO_RESET;
  sMasterConfig.MasterSlaveMode = TIM_MASTERSLAVEMODE_DISABLE;
  if (HAL_TIMEx_MasterConfigSynchronization(&htim3, &sMasterConfig) != HAL_OK)
  {
    Error_Handler();
  }
  sConfigOC.OCMode = TIM_OCMODE_PWM1;
  sConfigOC.Pulse = 0;
  sConfigOC.OCPolarity = TIM_OCPOLARITY_HIGH;
  sConfigOC.OCFastMode = TIM_OCFAST_DISABLE;
  if (HAL_TIM_PWM_ConfigChannel(&htim3, &sConfigOC, TIM_CHANNEL_1) != HAL_OK)
  {
    Error_Handler();
  }
  if (HAL_TIM_PWM_ConfigChannel(&htim3, &sConfigOC, TIM_CHANNEL_2) != HAL_OK)
  {
    Error_Handler();
  }
  if (HAL_TIM_PWM_ConfigChannel(&htim3, &sConfigOC, TIM_CHANNEL_3) != HAL_OK)
  {
    Error_Handler();
  }
  if (HAL_TIM_PWM_ConfigChannel(&htim3, &sConfigOC, TIM_CHANNEL_4) != HAL_OK)
  {
    Error_Handler();
  }
  HAL_TIM_MspPostInit(&htim3);

}

static void MX_TIM4_Init(void)
{

  TIM_MasterConfigTypeDef sMasterConfig = {0};
  TIM_IC_InitTypeDef sConfigIC = {0};

  htim4.Instance = TIM4;
  htim4.Init.Prescaler = 33;
  htim4.Init.CounterMode = TIM_COUNTERMODE_UP;
  htim4.Init.Period = 60000;
  htim4.Init.ClockDivision = TIM_CLOCKDIVISION_DIV1;
  htim4.Init.AutoReloadPreload = TIM_AUTORELOAD_PRELOAD_DISABLE;
  if (HAL_TIM_IC_Init(&htim4) != HAL_OK)
  {
    Error_Handler();
  }
  sMasterConfig.MasterOutputTrigger = TIM_TRGO_RESET;
  sMasterConfig.MasterSlaveMode = TIM_MASTERSLAVEMODE_DISABLE;
  if (HAL_TIMEx_MasterConfigSynchronization(&htim4, &sMasterConfig) != HAL_OK)
  {
    Error_Handler();
  }
  sConfigIC.ICPolarity = TIM_INPUTCHANNELPOLARITY_RISING;
  sConfigIC.ICSelection = TIM_ICSELECTION_DIRECTTI;
  sConfigIC.ICPrescaler = TIM_ICPSC_DIV1;
  sConfigIC.ICFilter = 0;
  if (HAL_TIM_IC_ConfigChannel(&htim4, &sConfigIC, TIM_CHANNEL_1) != HAL_OK)
  {
    Error_Handler();
  }
  if (HAL_TIM_IC_ConfigChannel(&htim4, &sConfigIC, TIM_CHANNEL_2) != HAL_OK)
  {
    Error_Handler();
  }
  if (HAL_TIM_IC_ConfigChannel(&htim4, &sConfigIC, TIM_CHANNEL_3) != HAL_OK)
  {
    Error_Handler();
  }
  if (HAL_TIM_IC_ConfigChannel(&htim4, &sConfigIC, TIM_CHANNEL_4) != HAL_OK)
  {
    Error_Handler();
  }

}

static void MX_TIM5_Init(void)
{

  TIM_MasterConfigTypeDef sMasterConfig = {0};
  TIM_IC_InitTypeDef sConfigIC = {0};

  htim5.Instance = TIM5;
  htim5.Init.Prescaler = 33;
  htim5.Init.CounterMode = TIM_COUNTERMODE_UP;
  htim5.Init.Period = 60000;
  htim5.Init.ClockDivision = TIM_CLOCKDIVISION_DIV1;
  htim5.Init.AutoReloadPreload = TIM_AUTORELOAD_PRELOAD_DISABLE;
  if (HAL_TIM_IC_Init(&htim5) != HAL_OK)
  {
    Error_Handler();
  }
  sMasterConfig.MasterOutputTrigger = TIM_TRGO_RESET;
  sMasterConfig.MasterSlaveMode = TIM_MASTERSLAVEMODE_DISABLE;
  if (HAL_TIMEx_MasterConfigSynchronization(&htim5, &sMasterConfig) != HAL_OK)
  {
    Error_Handler();
  }
  sConfigIC.ICPolarity = TIM_INPUTCHANNELPOLARITY_RISING;
  sConfigIC.ICSelection = TIM_ICSELECTION_DIRECTTI;
  sConfigIC.ICPrescaler = TIM_ICPSC_DIV1;
  sConfigIC.ICFilter = 0;
  if (HAL_TIM_IC_ConfigChannel(&htim5, &sConfigIC, TIM_CHANNEL_1) != HAL_OK)
  {
    Error_Handler();
  }
  if (HAL_TIM_IC_ConfigChannel(&htim5, &sConfigIC, TIM_CHANNEL_2) != HAL_OK)
  {
    Error_Handler();
  }
  if (HAL_TIM_IC_ConfigChannel(&htim5, &sConfigIC, TIM_CHANNEL_3) != HAL_OK)
  {
    Error_Handler();
  }
  if (HAL_TIM_IC_ConfigChannel(&htim5, &sConfigIC, TIM_CHANNEL_4) != HAL_OK)
  {
    Error_Handler();
  }

}

static void MX_UART5_Init(void)
{

  LL_USART_InitTypeDef USART_InitStruct = {0};

  LL_GPIO_InitTypeDef GPIO_InitStruct = {0};
  RCC_PeriphCLKInitTypeDef PeriphClkInitStruct = {0};

  /** Initializes the peripherals clock
  */
  PeriphClkInitStruct.PeriphClockSelection = RCC_PERIPHCLK_UART5;
  PeriphClkInitStruct.Uart5ClockSelection = RCC_UART5CLKSOURCE_PCLK1;
  if (HAL_RCCEx_PeriphCLKConfig(&PeriphClkInitStruct) != HAL_OK)
  {
    Error_Handler();
  }

  /* Peripheral clock enable */
  LL_APB1_GRP1_EnableClock(LL_APB1_GRP1_PERIPH_UART5);

  LL_AHB1_GRP1_EnableClock(LL_AHB1_GRP1_PERIPH_GPIOB);
  /**UART5 GPIO Configuration
  PB12   ------> UART5_RX
  PB13   ------> UART5_TX
  */
  GPIO_InitStruct.Pin = LL_GPIO_PIN_12;
  GPIO_InitStruct.Mode = LL_GPIO_MODE_ALTERNATE;
  GPIO_InitStruct.Speed = LL_GPIO_SPEED_FREQ_VERY_HIGH;
  GPIO_InitStruct.OutputType = LL_GPIO_OUTPUT_PUSHPULL;
  GPIO_InitStruct.Pull = LL_GPIO_PULL_NO;
  GPIO_InitStruct.Alternate = LL_GPIO_AF_8;
  LL_GPIO_Init(GPIOB, &GPIO_InitStruct);

  GPIO_InitStruct.Pin = LL_GPIO_PIN_13;
  GPIO_InitStruct.Mode = LL_GPIO_MODE_ALTERNATE;
  GPIO_InitStruct.Speed = LL_GPIO_SPEED_FREQ_VERY_HIGH;
  GPIO_InitStruct.OutputType = LL_GPIO_OUTPUT_PUSHPULL;
  GPIO_InitStruct.Pull = LL_GPIO_PULL_NO;
  GPIO_InitStruct.Alternate = LL_GPIO_AF_8;
  LL_GPIO_Init(GPIOB, &GPIO_InitStruct);

  /* UART5 interrupt Init */
  NVIC_SetPriority(UART5_IRQn, NVIC_EncodePriority(NVIC_GetPriorityGrouping(),0, 0));
  NVIC_EnableIRQ(UART5_IRQn);

  USART_InitStruct.BaudRate = 115200;
  USART_InitStruct.DataWidth = LL_USART_DATAWIDTH_8B;
  USART_InitStruct.StopBits = LL_USART_STOPBITS_1;
  USART_InitStruct.Parity = LL_USART_PARITY_NONE;
  USART_InitStruct.TransferDirection = LL_USART_DIRECTION_TX_RX;
  USART_InitStruct.HardwareFlowControl = LL_USART_HWCONTROL_NONE;
  USART_InitStruct.OverSampling = LL_USART_OVERSAMPLING_16;
  LL_USART_Init(UART5, &USART_InitStruct);
  LL_USART_ConfigAsyncMode(UART5);
  LL_USART_Enable(UART5);

}

static void MX_USART1_UART_Init(void)
{

  LL_USART_InitTypeDef USART_InitStruct = {0};

  LL_GPIO_InitTypeDef GPIO_InitStruct = {0};
  RCC_PeriphCLKInitTypeDef PeriphClkInitStruct = {0};

  /** Initializes the peripherals clock
  */
  PeriphClkInitStruct.PeriphClockSelection = RCC_PERIPHCLK_USART1;
  PeriphClkInitStruct.Usart1ClockSelection = RCC_USART1CLKSOURCE_PCLK2;
  if (HAL_RCCEx_PeriphCLKConfig(&PeriphClkInitStruct) != HAL_OK)
  {
    Error_Handler();
  }

  /* Peripheral clock enable */
  LL_APB2_GRP1_EnableClock(LL_APB2_GRP1_PERIPH_USART1);

  LL_AHB1_GRP1_EnableClock(LL_AHB1_GRP1_PERIPH_GPIOB);
  /**USART1 GPIO Configuration
  PB14   ------> USART1_TX
  PB15   ------> USART1_RX
  */
  GPIO_InitStruct.Pin = LL_GPIO_PIN_14;
  GPIO_InitStruct.Mode = LL_GPIO_MODE_ALTERNATE;
  GPIO_InitStruct.Speed = LL_GPIO_SPEED_FREQ_VERY_HIGH;
  GPIO_InitStruct.OutputType = LL_GPIO_OUTPUT_PUSHPULL;
  GPIO_InitStruct.Pull = LL_GPIO_PULL_NO;
  GPIO_InitStruct.Alternate = LL_GPIO_AF_4;
  LL_GPIO_Init(GPIOB, &GPIO_InitStruct);

  GPIO_InitStruct.Pin = LL_GPIO_PIN_15;
  GPIO_InitStruct.Mode = LL_GPIO_MODE_ALTERNATE;
  GPIO_InitStruct.Speed = LL_GPIO_SPEED_FREQ_VERY_HIGH;
  GPIO_InitStruct.OutputType = LL_GPIO_OUTPUT_PUSHPULL;
  GPIO_InitStruct.Pull = LL_GPIO_PULL_NO;
  GPIO_InitStruct.Alternate = LL_GPIO_AF_4;
  LL_GPIO_Init(GPIOB, &GPIO_InitStruct);

  /* USART1 interrupt Init */
  NVIC_SetPriority(USART1_IRQn, NVIC_EncodePriority(NVIC_GetPriorityGrouping(),0, 0));
  NVIC_EnableIRQ(USART1_IRQn);

  USART_InitStruct.BaudRate = 115200;
  USART_InitStruct.DataWidth = LL_USART_DATAWIDTH_8B;
  USART_InitStruct.StopBits = LL_USART_STOPBITS_1;
  USART_InitStruct.Parity = LL_USART_PARITY_NONE;
  USART_InitStruct.TransferDirection = LL_USART_DIRECTION_TX_RX;
  USART_InitStruct.HardwareFlowControl = LL_USART_HWCONTROL_NONE;
  USART_InitStruct.OverSampling = LL_USART_OVERSAMPLING_16;
  LL_USART_Init(USART1, &USART_InitStruct);
  LL_USART_ConfigAsyncMode(USART1);
  LL_USART_Enable(USART1);

}

static void MX_USART2_UART_Init(void)
{

  LL_USART_InitTypeDef USART_InitStruct = {0};

  LL_GPIO_InitTypeDef GPIO_InitStruct = {0};
  RCC_PeriphCLKInitTypeDef PeriphClkInitStruct = {0};

  /** Initializes the peripherals clock
  */
  PeriphClkInitStruct.PeriphClockSelection = RCC_PERIPHCLK_USART2;
  PeriphClkInitStruct.Usart2ClockSelection = RCC_USART2CLKSOURCE_PCLK1;
  if (HAL_RCCEx_PeriphCLKConfig(&PeriphClkInitStruct) != HAL_OK)
  {
    Error_Handler();
  }

  /* Peripheral clock enable */
  LL_APB1_GRP1_EnableClock(LL_APB1_GRP1_PERIPH_USART2);

  LL_AHB1_GRP1_EnableClock(LL_AHB1_GRP1_PERIPH_GPIOD);
  /**USART2 GPIO Configuration
  PD5   ------> USART2_TX
  PD6   ------> USART2_RX
  */
  GPIO_InitStruct.Pin = LL_GPIO_PIN_5;
  GPIO_InitStruct.Mode = LL_GPIO_MODE_ALTERNATE;
  GPIO_InitStruct.Speed = LL_GPIO_SPEED_FREQ_VERY_HIGH;
  GPIO_InitStruct.OutputType = LL_GPIO_OUTPUT_PUSHPULL;
  GPIO_InitStruct.Pull = LL_GPIO_PULL_NO;
  GPIO_InitStruct.Alternate = LL_GPIO_AF_7;
  LL_GPIO_Init(GPIOD, &GPIO_InitStruct);

  GPIO_InitStruct.Pin = LL_GPIO_PIN_6;
  GPIO_InitStruct.Mode = LL_GPIO_MODE_ALTERNATE;
  GPIO_InitStruct.Speed = LL_GPIO_SPEED_FREQ_VERY_HIGH;
  GPIO_InitStruct.OutputType = LL_GPIO_OUTPUT_PUSHPULL;
  GPIO_InitStruct.Pull = LL_GPIO_PULL_NO;
  GPIO_InitStruct.Alternate = LL_GPIO_AF_7;
  LL_GPIO_Init(GPIOD, &GPIO_InitStruct);

  /* USART2 interrupt Init */
  NVIC_SetPriority(USART2_IRQn, NVIC_EncodePriority(NVIC_GetPriorityGrouping(),0, 0));
  NVIC_EnableIRQ(USART2_IRQn);

  USART_InitStruct.BaudRate = 115200;
  USART_InitStruct.DataWidth = LL_USART_DATAWIDTH_8B;
  USART_InitStruct.StopBits = LL_USART_STOPBITS_1;
  USART_InitStruct.Parity = LL_USART_PARITY_NONE;
  USART_InitStruct.TransferDirection = LL_USART_DIRECTION_TX_RX;
  USART_InitStruct.HardwareFlowControl = LL_USART_HWCONTROL_NONE;
  USART_InitStruct.OverSampling = LL_USART_OVERSAMPLING_16;
  LL_USART_Init(USART2, &USART_InitStruct);
  LL_USART_ConfigAsyncMode(USART2);
  LL_USART_Enable(USART2);

}

static void MX_USART3_UART_Init(void)
{

  LL_USART_InitTypeDef USART_InitStruct = {0};

  LL_GPIO_InitTypeDef GPIO_InitStruct = {0};
  RCC_PeriphCLKInitTypeDef PeriphClkInitStruct = {0};

  /** Initializes the peripherals clock
  */
  PeriphClkInitStruct.PeriphClockSelection = RCC_PERIPHCLK_USART3;
  PeriphClkInitStruct.Usart3ClockSelection = RCC_USART3CLKSOURCE_PCLK1;
  if (HAL_RCCEx_PeriphCLKConfig(&PeriphClkInitStruct) != HAL_OK)
  {
    Error_Handler();
  }

  /* Peripheral clock enable */
  LL_APB1_GRP1_EnableClock(LL_APB1_GRP1_PERIPH_USART3);

  LL_AHB1_GRP1_EnableClock(LL_AHB1_GRP1_PERIPH_GPIOD);
  /**USART3 GPIO Configuration
  PD8   ------> USART3_TX
  PD9   ------> USART3_RX
  */
  GPIO_InitStruct.Pin = LL_GPIO_PIN_8;
  GPIO_InitStruct.Mode = LL_GPIO_MODE_ALTERNATE;
  GPIO_InitStruct.Speed = LL_GPIO_SPEED_FREQ_VERY_HIGH;
  GPIO_InitStruct.OutputType = LL_GPIO_OUTPUT_PUSHPULL;
  GPIO_InitStruct.Pull = LL_GPIO_PULL_NO;
  GPIO_InitStruct.Alternate = LL_GPIO_AF_7;
  LL_GPIO_Init(GPIOD, &GPIO_InitStruct);

  GPIO_InitStruct.Pin = LL_GPIO_PIN_9;
  GPIO_InitStruct.Mode = LL_GPIO_MODE_ALTERNATE;
  GPIO_InitStruct.Speed = LL_GPIO_SPEED_FREQ_VERY_HIGH;
  GPIO_InitStruct.OutputType = LL_GPIO_OUTPUT_PUSHPULL;
  GPIO_InitStruct.Pull = LL_GPIO_PULL_NO;
  GPIO_InitStruct.Alternate = LL_GPIO_AF_7;
  LL_GPIO_Init(GPIOD, &GPIO_InitStruct);

  /* USART3 interrupt Init */
  NVIC_SetPriority(USART3_IRQn, NVIC_EncodePriority(NVIC_GetPriorityGrouping(),0, 0));
  NVIC_EnableIRQ(USART3_IRQn);

  USART_InitStruct.BaudRate = 115200;
  USART_InitStruct.DataWidth = LL_USART_DATAWIDTH_8B;
  USART_InitStruct.StopBits = LL_USART_STOPBITS_1;
  USART_InitStruct.Parity = LL_USART_PARITY_NONE;
  USART_InitStruct.TransferDirection = LL_USART_DIRECTION_TX_RX;
  USART_InitStruct.HardwareFlowControl = LL_USART_HWCONTROL_NONE;
  USART_InitStruct.OverSampling = LL_USART_OVERSAMPLING_16;
  LL_USART_Init(USART3, &USART_InitStruct);
  LL_USART_ConfigAsyncMode(USART3);
  LL_USART_Enable(USART3);

}

static void MX_GPIO_Init(void)
{
  GPIO_InitTypeDef GPIO_InitStruct = {0};

  /* GPIO Ports Clock Enable */
  __HAL_RCC_GPIOE_CLK_ENABLE();
  __HAL_RCC_GPIOH_CLK_ENABLE();
  __HAL_RCC_GPIOC_CLK_ENABLE();
  __HAL_RCC_GPIOA_CLK_ENABLE();
  __HAL_RCC_GPIOB_CLK_ENABLE();
  __HAL_RCC_GPIOD_CLK_ENABLE();

  /*Configure GPIO pin Output Level */
  HAL_GPIO_WritePin(GPIOE, LED_R_Pin|LED_G_Pin|LED_B_Pin, GPIO_PIN_RESET);

  /*Configure GPIO pin Output Level */
  HAL_GPIO_WritePin(BUZZER_GPIO_Port, BUZZER_Pin, GPIO_PIN_RESET);

  /*Configure GPIO pin Output Level */
  HAL_GPIO_WritePin(GPIOD, KEY1_Pin|KEY2_Pin|KEY3_Pin|KEY4_Pin, GPIO_PIN_RESET);

  /*Configure GPIO pins : LED_R_Pin LED_G_Pin LED_B_Pin */
  GPIO_InitStruct.Pin = LED_R_Pin|LED_G_Pin|LED_B_Pin;
  GPIO_InitStruct.Mode = GPIO_MODE_OUTPUT_PP;
  GPIO_InitStruct.Pull = GPIO_NOPULL;
  GPIO_InitStruct.Speed = GPIO_SPEED_FREQ_LOW;
  HAL_GPIO_Init(GPIOE, &GPIO_InitStruct);

  /*Configure GPIO pin : BUZZER_Pin */
  GPIO_InitStruct.Pin = BUZZER_Pin;
  GPIO_InitStruct.Mode = GPIO_MODE_OUTPUT_PP;
  GPIO_InitStruct.Pull = GPIO_NOPULL;
  GPIO_InitStruct.Speed = GPIO_SPEED_FREQ_LOW;
  HAL_GPIO_Init(BUZZER_GPIO_Port, &GPIO_InitStruct);

  /*Configure GPIO pins : KEY1_Pin KEY2_Pin KEY3_Pin KEY4_Pin */
  GPIO_InitStruct.Pin = KEY1_Pin|KEY2_Pin|KEY3_Pin|KEY4_Pin;
  GPIO_InitStruct.Mode = GPIO_MODE_OUTPUT_PP;
  GPIO_InitStruct.Pull = GPIO_NOPULL;
  GPIO_InitStruct.Speed = GPIO_SPEED_FREQ_LOW;
  HAL_GPIO_Init(GPIOD, &GPIO_InitStruct);

}

/* USER CODE BEGIN 4 */
/*
*********************************************************************************************************
*	函 数 名: PrintfLogo
*	功能说明: 打印例程名称和例程发布日期, 接上串口线后，打开PC机的超级终端软件可以观察结果
*	形    参：无
*	返 回 值: 无
*********************************************************************************************************
*/
static void PrintfLogo(void)
{
	printf("*************************************************************\n\r");
	printf("* 例程名称   : %s\r\n", EXAMPLE_NAME);	/* 打印例程名称 */
	printf("* 例程版本   : %s\r\n", DEMO_VER);		/* 打印例程版本 */
	printf("* 发布日期   : %s\r\n", EXAMPLE_DATE);	/* 打印例程日期 */

	/* 打印ST固件库版本，这3个定义宏在stm32f40x.h文件中 */
	printf("* 固件库版本 :STM32F10x_StdPeriph_Driver)\r\n");
	printf("* \n\r");	/* 打印一行空格 */
	printf("* QQ    : 665836518 \r\n");
	printf("* 淘宝店地址 : https://shop144519723.taobao.com/index.htm?spm=2013.1.w5002-13163471369.2.71db1223NyFC4j \r\n");
	printf("* 梦创电子 \r\n");
	printf("*************************************************************\n\r");
}

/*
*********************************************************************************************************
*	函 数 名: PrintfHardInfo
*	功能说明: 打印硬件接线信息
*	形    参：无
*	返 回 值: 无
*********************************************************************************************************
*/
static void PrintfHardInfo(void)
{
  printf("*****************************************************************\r\n");
	printf("  接线方法: \r\n");
	printf("**梦创电子四旋翼飞行器室内自动飞行****\r\n");
  printf("  +5V       <------   5.0V      5V供电\r\n");
  printf("  GND       -------   GND       地\r\n");
	printf("  PB0       ------>   PWM3      与遥控器的pitch通道相连\r\n");
	printf("  PB1       ------>   PWM4      与遥控器的接收机的第五通道相连 \r\n");
	printf("  PA6       ------>   PWM1      与遥控器接收机油门相连 \r\n");
	printf("  PB7       ------>   PWM2      与遥控器的偏航通道(YAW)相连\r\n");
	printf("  PA0       ------>   ADC_CH1   模拟超声波高度测量\r\n");
	printf("  打印采集数据: \r\n");
	printf("*****************************************************************\r\n");
}

unsigned short CRC_CHECK(unsigned char *Buf, unsigned char CRC_CNT)
{
    unsigned short CRC_Temp;
    unsigned char i,j;
    CRC_Temp = 0xffff;

    for (i=0;i<CRC_CNT; i++){
        CRC_Temp ^= Buf[i];
        for (j=0;j<8;j++) {
            if (CRC_Temp & 0x01)
                CRC_Temp = (CRC_Temp >>1 ) ^ 0xa001;
            else
                CRC_Temp = CRC_Temp >> 1;
        }
    }
    return(CRC_Temp);
}

//*********************OutPut_Data****************************************//
void OutPut_Data(void)
{
  int temp[4] = {0};
  unsigned int temp1[4] = {0};
  unsigned char databuf[10] = {0};
  unsigned char i;
  unsigned short CRC16 = 0;
  for(i=0;i<4;i++)
   {

    temp[i]  = (int16_t)OutData[i];
    temp1[i] = (int16_t)temp[i];

   }

  for(i=0;i<4;i++)
  {
    databuf[i*2]   = (int8_t)(temp1[i]%256);
    databuf[i*2+1] = (int8_t)(temp1[i]/256);
  }

  CRC16 = CRC_CHECK(databuf,8);
  databuf[8] = CRC16%256;
  databuf[9] = CRC16/256;

  for(i=0;i<10;i++)
	{
		BSP_USART_SendArray_LL( USART1,databuf,sizeof(databuf));
		//HAL_UART_Transmit(&huart1,(uint8_t *)&databuf[i],1,10);       //串口发送
	}
}

//****************************Data_to_VisualScope***************************************//
void Data_to_VisualScope(void)
{
		int16_t i;
    for(i = 0; i < CH_NUM; i++)
    {
      OutData[i] = s_volt[i];
      OutPut_Data();
    }
}

/*
*********************************************************************************************************
*	函 数 名: AD转化函数
*	功能说明: 处理采样后的数据
*	形    参：无
*	返 回 值: 无
*********************************************************************************************************
*/
float ADC_CvtVolt(void)
{
	float volt=0;
	uint8_t i;
	int16_t adc;
	for(i=0;i<CH_NUM;i++)
	{

		HAL_ADC_Start(&hadc1);
		HAL_ADC_PollForConversion(&hadc1,0xffff);

		ADC_ReadBuffer[i] = HAL_ADC_GetValue(&hadc1);
		s_dat[i] = ADC_ReadBuffer[i];
		adc = s_dat[i];
		s_volt[i] = (adc * 3.30f) / 4096;
	}
	HAL_ADC_Stop(&hadc1);
	volt=s_volt[0]*voltage_ratio ;
	return  volt;
}

/*
*********************************************************************************************************
*	函 数 名: AD7606_Mak
*	功能说明: 处理采样后的数据
*	形    参：无
*	返 回 值: 无
*********************************************************************************************************
*/
float ADC_CvtVolt_and_filter(void)
{
	float ADC_read=0.0;
	ADC_read=filter_av(1);
	return  ADC_read;
}

//***********读取ADC****************//
float get_adc(char adc_id)
{
	float volt=0;
	int16_t adc;
	HAL_ADC_Start(&hadc1);
	HAL_ADC_PollForConversion(&hadc1,0xffff);

	adc=HAL_ADC_GetValue(&hadc1);
	volt = ((adc * 3.30f) / 4096)*voltage_ratio;
	HAL_ADC_Stop(&hadc1);
	HAL_Delay(1);
	//printf("V=%2.2f V Data_after_Deal=%2.2f cm  H=%2.2f cm  (count0=%4.1d) pwm_duty_out=%2.2f pwm_out=%d control_val=%2.2d \r\n",volt_0/voltage_ratio,Data_after_Deal,volt_0,count0,pwm_duty_out,PWM_Out,control_val);
	return  volt;
}

//********算数平均滤波法**************//
float filter_av(char filter_id)
{
	char count=0;
	float sum = 0.0;
	for ( count=0;count<N;count++)
	{
	 sum  = sum + get_adc(1);
	}
	return sum/N;
}

//************************************数据处理函数********************************//
float DataProcessing(float IN_Data)
{
	static float out_Data=0,last_Data=0,filter_Data=0; //static只初始化一次
	out_Data  = 0.7*IN_Data+0.3*last_Data;
	filter_Data  = filter(out_Data);
	last_Data = filter_Data;
	return filter_Data;
}

float filter(float new_value)
{
if(new_value>200)
	new_value=200;
if(new_value<10)
	new_value=10;
if ( ( new_value - old_value > A ) || ( old_value - new_value > A ))
 {
	old_value = old_value;
	return old_value;
 }
 old_value = new_value;
 return new_value;
}

/****************************串口中断回调*****************************/
void   USART_RxCallback(USART_TypeDef *huart)
{
	mavlink_message_t msg;
	mavlink_status_t status;

	if(LL_USART_IsActiveFlag_RXNE(huart) && LL_USART_IsEnabledIT_RXNE(huart))
  {
  //***********串口1中断**********************************
		if(huart == USART1)
		{
			uint8_t data = LL_USART_ReceiveData8(huart);
			if(data == 0x23)  //表示字符 '#',即约定的通信包开头
			{
				UART1_Frame_Flag = 1;
			}
			//printf("USART1_RX_STA =%d data = %d \r\n",USART1_RX_STA , data);
      if(((USART1_RX_STA  & (1<<15))==0) && (UART1_Frame_Flag == 1))	//还可以接收数据 ,最高位不为1.
			{
        TIM3->CNT=0;				//计数器清空
        if(USART1_RX_STA == 0)  //新一轮接收数据
        {
          Recv_Cnt_UART1 = 0;
          TIM3_Set(1);  //中断方式开启定时器3
        }
        USART1_RX_BUF[USART1_RX_STA++] = data;				//记录接收到的值
				Recv_Cnt_UART1 ++;  //计数值增1
				if(Recv_Cnt_UART1 >= 11){
          //接满一个通信包的长度
          Recv_Cnt_UART1=0;
          UART1_Frame_Flag = 0;
				 USART1_RX_STA |= 1<<15;				 //强制标记接收完成
			   LL_USART_DisableIT_RXNE(USART1);   //关闭接收非空中断
        }
			}
		}
	 //***********串口2中断，主要用于与Mavlink协议的设备连接*********************
		else if(huart == USART2)
		{
			uint8_t data = LL_USART_ReceiveData8(huart);
			if(data == 0xFE)    //根据mavlink包格式设置
			{
				UART2_Frame_Flag = 1;
			}
      if((USART2_RX_STA  & (1<<15))==0 && (UART2_Frame_Flag == 1))		//还可以接收数据 ,最高位不为1.
			{
				TIM5->CNT=0;				//计数器5清空
        if(USART2_RX_STA == 0)
				{
					TIM5_Set(1);	 	                //使能定时器1的中断
					Recv_Cnt_UART2 = 0;
				}
				USART2_RX_BUF[USART2_RX_STA++] = data;
				Recv_Cnt_UART2 ++;
				if(Recv_Cnt_UART2>=50)
				{
					Recv_Cnt_UART2 = 0;
					UART2_Frame_Flag = 0;
					USART2_RX_STA |= 1<<15;					//强制标记接收完成
					LL_USART_DisableIT_RXNE(USART2);
				}
			}
		}
    //*******************串口3中断****************
    else if(huart == USART3)
    {
      uint8_t data = LL_USART_ReceiveData8(huart);  //串口接收一个字节
      if(data == 0x23)  //表示字符 '#',即约定的通信包开头
      {
        UART3_Frame_Flag = 1;
      }
      if((USART3_RX_STA & (1<<15))==0 && (UART3_Frame_Flag==1))
      {
        TIM2->CNT = 0;    //定时器2清空
        if(USART3_RX_STA == 0)    //新一轮接收开始
        {
          TIM2_Set(1);
          Recv_Cnt_UART3 = 0;
        }
        USART3_RX_BUF[USART3_RX_STA++] = data;  //存入接收缓冲区
        Recv_Cnt_UART3 ++;  //接收计数
        if(Recv_Cnt_UART3>=11)   //接满一个通信包的长度
				{
          Recv_Cnt_UART3=0;
          UART3_Frame_Flag = 0;
				  USART3_RX_STA |= 1<<15;				 //强制标记接收完成
			    LL_USART_DisableIT_RXNE(USART3);   //关闭接收非空中断
				}
      }
    }
	}
}

//*******定时器中断服务程序	*************************************//
void HAL_TIM_PeriodElapsedCallback(TIM_HandleTypeDef *htim)
{
		static uint16_t tim3_1ms= 0;//中断次数计数器
	  static uint16_t tim5_1ms= 0;//中断次数计数器
    static uint16_t tim2_1ms= 0;//中断次数计数器

		 //*****定时器3中断服务函数->在串口1中使用到更新中断*********
		if (htim->Instance == htim3.Instance) //是更新中断
		{
			tim3_1ms++;
			if(tim3_1ms==5)		    //每5次中断执行一次,20ms X 5 -> 与其他模块发送数据的间隔相符合即可
			{
				USART1_RX_STA|= (1<<15);	//标记接收完成
				TIM3->SR&=~(1<<0);		//清除中断标志位
				TIM3_Set(0);			    //关闭TIM3
				tim3_1ms=0;
				//printf("TIME 4 INT \r\n");
			}
		}
		 //*****定时器5中断服务函数->用于串口2*********************
		if (htim->Instance == htim5.Instance) //是更新中断
		{
			tim5_1ms++;
			if(tim5_1ms==5)		    //每5次中断执行一次,20ms
			{
				USART2_RX_STA |= (1<<15);	//标记接收完成
				TIM5->SR&=~(1<<0);		//清除中断标志位
				TIM5_Set(0);			    //关闭TIM5
				tim5_1ms=0;
				//printf("TIME 5 INT \r\n");
			}
		}
     //*****定时器2中断服务函数->用于串口3*********************
		if (htim->Instance == htim2.Instance) //是更新中断
		{
			tim2_1ms++;
			if(tim5_1ms==5)		    //每5次中断执行一次,20ms
			{
				USART3_RX_STA |= (1<<15);	//标记接收完成
				TIM2->SR&=~(1<<0);		//清除中断标志位
				TIM2_Set(0);			    //关闭TIM5
				tim2_1ms=0;
				//printf("TIME 2 INT \r\n");
			}
		}
}

//定时器3
void TIM3_Set(uint8_t sta)
{
	if(sta)
	{
		TIM3->CNT=0;                   //计数器清空
		HAL_TIM_Base_Start_IT(&htim3); //使能定时器3
	}else
		HAL_TIM_Base_Stop_IT(&htim3);  //关闭定时器3
}
//定时器2
void TIM2_Set(uint8_t sta)
{
	if(sta)
	{
		TIM2->CNT=0;                   //计数器清空
		HAL_TIM_Base_Start_IT(&htim2); //使能定时器2
	}else
		HAL_TIM_Base_Stop_IT(&htim2);  //关闭定时器2
}

//定时器3
//********************************
//采用定时器轮询的方式实现延时。
//		for(int q=0;q<1000;q++)
//		{
//				Delay_us(1000);
//		}
//调用示例
//********************************

void TIM5_Set(uint8_t sta)
{
	if(sta)
	{
		TIM5->CNT=0;                   //计数器清空
		HAL_TIM_Base_Start_IT(&htim5); //使能定时器5
	}else
		HAL_TIM_Base_Stop_IT(&htim5);  //关闭定时器5
}

// 定时器输入捕获PWM
void HAL_TIM_IC_CaptureCallback(TIM_HandleTypeDef *htim)
{
	//printf("TIM_IC \r\n");
  TIM_IC_InitTypeDef sConfigIC;
	if(htim->Instance == htim4.Instance)
	{
		switch(htim->Channel)
		{
			case HAL_TIM_ACTIVE_CHANNEL_1:
				if(ICFLAG_1){
					CHANNEL_1_RISE = HAL_TIM_ReadCapturedValue(&htim4,TIM_CHANNEL_1);

					sConfigIC.ICPolarity  = TIM_INPUTCHANNELPOLARITY_FALLING;//下降沿
					sConfigIC.ICSelection = TIM_ICSELECTION_DIRECTTI;
					sConfigIC.ICPrescaler = TIM_ICPSC_DIV1;
					sConfigIC.ICFilter = 0;
					HAL_TIM_IC_Stop_IT(&htim4,TIM_CHANNEL_1);
					HAL_TIM_IC_ConfigChannel(&htim4, &sConfigIC, TIM_CHANNEL_1);

					__HAL_TIM_CLEAR_IT(&htim4, TIM_IT_CC1);
					if(HAL_TIM_IC_Start_IT(&htim4,TIM_CHANNEL_1)!= HAL_OK)
					{
						printf("ERROR\r\n");
					}

					ICFLAG_1 = 0;
				}
				else{
					CHANNEL_1_FALL = HAL_TIM_ReadCapturedValue(&htim4,TIM_CHANNEL_1);

					sConfigIC.ICPolarity = TIM_INPUTCHANNELPOLARITY_RISING;//上升沿
					sConfigIC.ICSelection = TIM_ICSELECTION_DIRECTTI;
					sConfigIC.ICPrescaler = TIM_ICPSC_DIV1;
					sConfigIC.ICFilter = 0;
					HAL_TIM_IC_Stop_IT(&htim4,TIM_CHANNEL_1);
					HAL_TIM_IC_ConfigChannel(&htim4, &sConfigIC, TIM_CHANNEL_1);

					__HAL_TIM_CLEAR_IT(&htim4, TIM_IT_CC1);
					if(HAL_TIM_IC_Start_IT(&htim4,TIM_CHANNEL_1)!= HAL_OK)
					{
						printf("ERROR\r\n");
					}

					CHANNEL_1_PULSE_WIDE = (CHANNEL_1_FALL > CHANNEL_1_RISE ? (CHANNEL_1_FALL - CHANNEL_1_RISE):(CHANNEL_1_FALL - CHANNEL_1_RISE + 60000));
					ICFLAG_1 = 1;
				}
				//CH1_PWM_test(CHANNEL_1_PULSE_WIDE);
//				printf("channel1 pulsewidth = %d \r\n", CHANNEL_1_PULSE_WIDE);
				break;
	//	 /*************************************************************************/
			case HAL_TIM_ACTIVE_CHANNEL_2:
					if(ICFLAG_2){
					CHANNEL_2_RISE = HAL_TIM_ReadCapturedValue(&htim4,TIM_CHANNEL_2);

					sConfigIC.ICPolarity = TIM_INPUTCHANNELPOLARITY_FALLING;//下降沿
					sConfigIC.ICSelection = TIM_ICSELECTION_DIRECTTI;
					sConfigIC.ICPrescaler = TIM_ICPSC_DIV1;
					sConfigIC.ICFilter = 0;
					HAL_TIM_IC_Stop_IT(&htim4,TIM_CHANNEL_2);
					////////////////////////////这里没有&，是漏打了还是本来就这样？
					HAL_TIM_IC_ConfigChannel(&htim4, &sConfigIC, TIM_CHANNEL_2);

					__HAL_TIM_CLEAR_IT(&htim4, TIM_IT_CC2);
					if(HAL_TIM_IC_Start_IT(&htim4,TIM_CHANNEL_2)!= HAL_OK)
					{
						printf("ERROR\r\n");
					}

					ICFLAG_2 = 0;
				}
				else{
					CHANNEL_2_FALL = HAL_TIM_ReadCapturedValue(&htim4,TIM_CHANNEL_2);

					sConfigIC.ICPolarity = TIM_INPUTCHANNELPOLARITY_RISING;//上升沿
					sConfigIC.ICSelection = TIM_ICSELECTION_DIRECTTI;
					sConfigIC.ICPrescaler = TIM_ICPSC_DIV1;
					sConfigIC.ICFilter = 0;
					HAL_TIM_IC_Stop_IT(&htim4,TIM_CHANNEL_2);
					HAL_TIM_IC_ConfigChannel(&htim4, &sConfigIC, TIM_CHANNEL_2);

					__HAL_TIM_CLEAR_IT(&htim4, TIM_IT_CC2);
					if(HAL_TIM_IC_Start_IT(&htim4,TIM_CHANNEL_2)!= HAL_OK)
					{
						printf("ERROR\r\n");
					}

					CHANNEL_2_PULSE_WIDE = (CHANNEL_2_FALL > CHANNEL_2_RISE ? CHANNEL_2_FALL - CHANNEL_2_RISE:CHANNEL_2_FALL - CHANNEL_2_RISE + 60000);
					ICFLAG_2 = 1;
				}
				//CH2_PWM_test(CHANNEL_2_PULSE_WIDE);
//				printf("channel2 pulsewidth = %d \r\n", CHANNEL_2_PULSE_WIDE);
				break;
	//	/**************************************************************************/
			case HAL_TIM_ACTIVE_CHANNEL_3:
				if(ICFLAG_3){
					CHANNEL_3_RISE = HAL_TIM_ReadCapturedValue(&htim4,TIM_CHANNEL_3);

					sConfigIC.ICPolarity = TIM_INPUTCHANNELPOLARITY_FALLING;//下降沿
					sConfigIC.ICSelection = TIM_ICSELECTION_DIRECTTI;
					sConfigIC.ICPrescaler = TIM_ICPSC_DIV1;
					sConfigIC.ICFilter = 0;
					HAL_TIM_IC_Stop_IT(&htim4,TIM_CHANNEL_3);
					HAL_TIM_IC_ConfigChannel(&htim4, &sConfigIC, TIM_CHANNEL_3);

					__HAL_TIM_CLEAR_IT(&htim4, TIM_IT_CC3);
					if(HAL_TIM_IC_Start_IT(&htim4,TIM_CHANNEL_3)!= HAL_OK)
					{
						printf("ERROR\r\n");
					}

					ICFLAG_3 = 0;
				}
				else{
					CHANNEL_3_FALL = HAL_TIM_ReadCapturedValue(&htim4,TIM_CHANNEL_3);

					sConfigIC.ICPolarity = TIM_INPUTCHANNELPOLARITY_RISING;//上升沿
					sConfigIC.ICSelection = TIM_ICSELECTION_DIRECTTI;
					sConfigIC.ICPrescaler = TIM_ICPSC_DIV1;
					sConfigIC.ICFilter = 0;
					HAL_TIM_IC_Stop_IT(&htim4,TIM_CHANNEL_3);
					HAL_TIM_IC_ConfigChannel(htim, &sConfigIC, TIM_CHANNEL_3);

					__HAL_TIM_CLEAR_IT(&htim4, TIM_IT_CC3);
					if(HAL_TIM_IC_Start_IT(&htim4,TIM_CHANNEL_3)!= HAL_OK)
					{
						printf("ERROR\r\n");
					}

					CHANNEL_3_PULSE_WIDE = (CHANNEL_3_FALL > CHANNEL_3_RISE ? CHANNEL_3_FALL - CHANNEL_3_RISE:CHANNEL_3_FALL - CHANNEL_3_RISE + 60000);
					ICFLAG_3 = 1;
				}
				//CH3_PWM_test(CHANNEL_3_PULSE_WIDE);
//				printf("channel3 pulsewidth = %d \r\n", CHANNEL_3_PULSE_WIDE);
				break;
	//			/**************************************************************************/
			case HAL_TIM_ACTIVE_CHANNEL_4:
				if(ICFLAG_4){
					CHANNEL_4_RISE = HAL_TIM_ReadCapturedValue(&htim4,TIM_CHANNEL_4);

					sConfigIC.ICPolarity = TIM_INPUTCHANNELPOLARITY_FALLING;//下降沿
					sConfigIC.ICSelection = TIM_ICSELECTION_DIRECTTI;
					sConfigIC.ICPrescaler = TIM_ICPSC_DIV1;
					sConfigIC.ICFilter = 0;
					HAL_TIM_IC_Stop_IT(&htim4,TIM_CHANNEL_4);
					HAL_TIM_IC_ConfigChannel(&htim4, &sConfigIC, TIM_CHANNEL_4);

					__HAL_TIM_CLEAR_IT(&htim4, TIM_IT_CC4);
					if(HAL_TIM_IC_Start_IT(&htim4,TIM_CHANNEL_4)!= HAL_OK)
					{
						printf("ERROR\r\n");
					}

					ICFLAG_4 = 0;
				}
				else{
					CHANNEL_4_FALL = HAL_TIM_ReadCapturedValue(&htim4,TIM_CHANNEL_4);

					sConfigIC.ICPolarity = TIM_INPUTCHANNELPOLARITY_RISING;//上升沿
					sConfigIC.ICSelection = TIM_ICSELECTION_DIRECTTI;
					sConfigIC.ICPrescaler = TIM_ICPSC_DIV1;
					sConfigIC.ICFilter = 0;
					HAL_TIM_IC_Stop_IT(&htim4,TIM_CHANNEL_4);
					////////////////同上
					HAL_TIM_IC_ConfigChannel(&htim4, &sConfigIC, TIM_CHANNEL_4);

					__HAL_TIM_CLEAR_IT(&htim4, TIM_IT_CC4);
					if(HAL_TIM_IC_Start_IT(&htim4,TIM_CHANNEL_4)!= HAL_OK)
					{
						printf("ERROR\r\n");
					}

					CHANNEL_4_PULSE_WIDE = (CHANNEL_4_FALL > CHANNEL_4_RISE ? CHANNEL_4_FALL - CHANNEL_4_RISE:CHANNEL_4_FALL - CHANNEL_4_RISE + 60000);
					ICFLAG_4 = 1;
				}
				//CH4_PWM_test(CHANNEL_3_PULSE_WIDE);
//				printf("channel4 pulsewidth = %d \r\n", CHANNEL_4_PULSE_WIDE);
				break;
			default: break;
		}
	}

	//****************************定时器1捕获****************************************
	if(htim->Instance == htim5.Instance)
	{
		switch(htim->Channel)
		{
			case HAL_TIM_ACTIVE_CHANNEL_1:
				if(ICFLAG_5){
					CHANNEL_5_RISE = HAL_TIM_ReadCapturedValue(&htim5,TIM_CHANNEL_1);

					sConfigIC.ICPolarity = TIM_INPUTCHANNELPOLARITY_FALLING;//下降沿
					sConfigIC.ICSelection = TIM_ICSELECTION_DIRECTTI;
					sConfigIC.ICPrescaler = TIM_ICPSC_DIV1;
					sConfigIC.ICFilter = 0;
					HAL_TIM_IC_Stop_IT(&htim5,TIM_CHANNEL_1);
					HAL_TIM_IC_ConfigChannel(&htim5, &sConfigIC, TIM_CHANNEL_1);

					__HAL_TIM_CLEAR_IT(&htim5, TIM_IT_CC1);
					HAL_TIM_IC_Start_IT(&htim5,TIM_CHANNEL_1);

					ICFLAG_5 = 0;
				}
				else{
					CHANNEL_5_FALL = HAL_TIM_ReadCapturedValue(&htim5,TIM_CHANNEL_1);

					sConfigIC.ICPolarity = TIM_INPUTCHANNELPOLARITY_RISING;//上升沿
					sConfigIC.ICSelection = TIM_ICSELECTION_DIRECTTI;
					sConfigIC.ICPrescaler = TIM_ICPSC_DIV1;
					sConfigIC.ICFilter = 0;
					HAL_TIM_IC_Stop_IT(&htim5,TIM_CHANNEL_1);
					HAL_TIM_IC_ConfigChannel(&htim5, &sConfigIC, TIM_CHANNEL_1);

				__HAL_TIM_CLEAR_IT(&htim5, TIM_IT_CC1);
					HAL_TIM_IC_Start_IT(&htim5,TIM_CHANNEL_1);

					CHANNEL_5_PULSE_WIDE = (CHANNEL_5_FALL > CHANNEL_5_RISE ? CHANNEL_5_FALL - CHANNEL_5_RISE:CHANNEL_5_FALL - CHANNEL_5_RISE + 60000);
					ICFLAG_5 = 1;
				}
				//CH1_PWM_test(CHANNEL_1_PULSE_WIDE);
//				printf("channel5 pulsewidth = %d \r\n", CHANNEL_5_PULSE_WIDE);
				break;
			case HAL_TIM_ACTIVE_CHANNEL_2:
				if(ICFLAG_6){
					CHANNEL_6_RISE = HAL_TIM_ReadCapturedValue(&htim5,TIM_CHANNEL_2);

					sConfigIC.ICPolarity = TIM_INPUTCHANNELPOLARITY_FALLING;//下降沿
					sConfigIC.ICSelection = TIM_ICSELECTION_DIRECTTI;
					sConfigIC.ICPrescaler = TIM_ICPSC_DIV1;
					sConfigIC.ICFilter = 0;
					HAL_TIM_IC_Stop_IT(&htim5,TIM_CHANNEL_2);
					HAL_TIM_IC_ConfigChannel(&htim5, &sConfigIC, TIM_CHANNEL_2);

					__HAL_TIM_CLEAR_IT(&htim5, TIM_IT_CC2);
					HAL_TIM_IC_Start_IT(&htim5,TIM_CHANNEL_2);

					ICFLAG_6 = 0;
				}
				else{
					CHANNEL_6_FALL = HAL_TIM_ReadCapturedValue(&htim5,TIM_CHANNEL_2);

					sConfigIC.ICPolarity = TIM_INPUTCHANNELPOLARITY_RISING;//上升沿
					sConfigIC.ICSelection = TIM_ICSELECTION_DIRECTTI;
					sConfigIC.ICPrescaler = TIM_ICPSC_DIV1;
					sConfigIC.ICFilter = 0;
					HAL_TIM_IC_Stop_IT(&htim5,TIM_CHANNEL_2);
					HAL_TIM_IC_ConfigChannel(&htim5, &sConfigIC, TIM_CHANNEL_2);

				__HAL_TIM_CLEAR_IT(&htim5, TIM_IT_CC2);
					HAL_TIM_IC_Start_IT(&htim5,TIM_CHANNEL_2);

					CHANNEL_6_PULSE_WIDE = (CHANNEL_6_FALL > CHANNEL_6_RISE ? CHANNEL_6_FALL - CHANNEL_6_RISE:CHANNEL_6_FALL - CHANNEL_6_RISE + 60000);
					ICFLAG_6 = 1;
				}
				//CH1_PWM_test(CHANNEL_1_PULSE_WIDE);
//				printf("channel5 pulsewidth = %d \r\n", CHANNEL_5_PULSE_WIDE);
				break;
			case HAL_TIM_ACTIVE_CHANNEL_3:
				if(ICFLAG_7){
					CHANNEL_7_RISE = HAL_TIM_ReadCapturedValue(&htim5,TIM_CHANNEL_3);

					sConfigIC.ICPolarity = TIM_INPUTCHANNELPOLARITY_FALLING;//下降沿
					sConfigIC.ICSelection = TIM_ICSELECTION_DIRECTTI;
					sConfigIC.ICPrescaler = TIM_ICPSC_DIV1;
					sConfigIC.ICFilter = 0;
					HAL_TIM_IC_Stop_IT(&htim5,TIM_CHANNEL_3);
					HAL_TIM_IC_ConfigChannel(&htim5, &sConfigIC, TIM_CHANNEL_3);

					__HAL_TIM_CLEAR_IT(&htim5, TIM_IT_CC3);
					HAL_TIM_IC_Start_IT(&htim5,TIM_CHANNEL_3);

					ICFLAG_7 = 0;
				}
				else{
					CHANNEL_7_FALL = HAL_TIM_ReadCapturedValue(&htim5,TIM_CHANNEL_3);

					sConfigIC.ICPolarity = TIM_INPUTCHANNELPOLARITY_RISING;//上升沿
					sConfigIC.ICSelection = TIM_ICSELECTION_DIRECTTI;
					sConfigIC.ICPrescaler = TIM_ICPSC_DIV1;
					sConfigIC.ICFilter = 0;
					HAL_TIM_IC_Stop_IT(&htim5,TIM_CHANNEL_3);
					HAL_TIM_IC_ConfigChannel(&htim5, &sConfigIC, TIM_CHANNEL_3);

				__HAL_TIM_CLEAR_IT(&htim5, TIM_IT_CC3);
					HAL_TIM_IC_Start_IT(&htim5,TIM_CHANNEL_3);

					CHANNEL_7_PULSE_WIDE = (CHANNEL_7_FALL > CHANNEL_7_RISE ? CHANNEL_7_FALL - CHANNEL_7_RISE:CHANNEL_7_FALL - CHANNEL_7_RISE + 60000);
					ICFLAG_7 = 1;
				}
				//CH1_PWM_test(CHANNEL_1_PULSE_WIDE);
//				printf("channel5 pulsewidth = %d \r\n", CHANNEL_5_PULSE_WIDE);
				break;
		 /*************************************************************************/
			case HAL_TIM_ACTIVE_CHANNEL_4:
					if(ICFLAG_8){
					CHANNEL_8_RISE = HAL_TIM_ReadCapturedValue(&htim5,TIM_CHANNEL_4);

					sConfigIC.ICPolarity = TIM_INPUTCHANNELPOLARITY_FALLING;//下降沿
					sConfigIC.ICSelection = TIM_ICSELECTION_DIRECTTI;
					sConfigIC.ICPrescaler = TIM_ICPSC_DIV1;
					sConfigIC.ICFilter = 0;
					HAL_TIM_IC_Stop_IT(&htim5,TIM_CHANNEL_4);
					HAL_TIM_IC_ConfigChannel(&htim5, &sConfigIC, TIM_CHANNEL_4);

					__HAL_TIM_CLEAR_IT(htim, TIM_IT_CC4);
					HAL_TIM_IC_Start_IT(htim,TIM_CHANNEL_4);

					ICFLAG_8 = 0;
				}
				else{
					CHANNEL_8_FALL = HAL_TIM_ReadCapturedValue(&htim5,TIM_CHANNEL_4);

					sConfigIC.ICPolarity = TIM_INPUTCHANNELPOLARITY_RISING;//上升沿
					sConfigIC.ICSelection = TIM_ICSELECTION_DIRECTTI;
					sConfigIC.ICPrescaler = TIM_ICPSC_DIV1;
					sConfigIC.ICFilter = 0;
					HAL_TIM_IC_Stop_IT(&htim5,TIM_CHANNEL_4);
					HAL_TIM_IC_ConfigChannel(&htim5, &sConfigIC, TIM_CHANNEL_4);

					__HAL_TIM_CLEAR_IT(&htim5, TIM_IT_CC4);
					HAL_TIM_IC_Start_IT(&htim5,TIM_CHANNEL_4);

					CHANNEL_8_PULSE_WIDE = (CHANNEL_8_FALL > CHANNEL_8_RISE ? CHANNEL_8_FALL - CHANNEL_8_RISE:CHANNEL_8_FALL - CHANNEL_8_RISE + 60000);
					ICFLAG_8 = 1;
				}
				//CH2_PWM_test(CHANNEL_2_PULSE_WIDE);
//				printf("channel6 pulsewidth = %d \r\n", CHANNEL_6_PULSE_WIDE);
				break;
			default: break;
		}
	}
}

//手动发送mavlink信号
void MANUAL_CONTROL_Send(int16_t xpoint,int16_t ypoint)
{
	uint8_t system_id = 255;          // 发送本条消息帧的设备的系统编号（sys）
	uint8_t component_id = 0;         // 发送本条消息帧的设备的单元编号（comp）
	uint8_t target = 0x01;            //目标系统
	int16_t x=0;
	int16_t y=ypoint;
	int16_t z=0;
	int16_t r=0;
	uint16_t buttons=0;
	mavlink_message_t msg;             // msg The MAVLink message to compress the data into
	uint8_t buf[MAVLINK_MAX_PACKET_LEN];
	uint16_t len;

	mavlink_msg_manual_control_pack(system_id, component_id, &msg, target,x,y,z,r,buttons);
	len = mavlink_msg_to_send_buffer(buf, &msg);
	//UART_Send_Str(buf,len);
	BSP_USART_SendArray_LL( USART1,buf,sizeof(buf));
}

void RC_CHANNELS_OVERRIDE_Send(int16_t xpoint,int16_t ypoint)
{
	uint8_t system_id=255;
	uint8_t component_id=0;
	mavlink_message_t msg;
	uint8_t target_system=1;
	uint8_t target_component=0;
	uint16_t chan1_raw=ypoint;
	uint16_t chan2_raw=65535;
	uint16_t chan3_raw=65535;
	uint16_t chan4_raw=65535;
	uint16_t chan5_raw=65535;
	uint16_t chan6_raw=65535;
	uint16_t chan7_raw=65535;
	uint16_t chan8_raw=65535;
	uint8_t buf[MAVLINK_MAX_PACKET_LEN];
	uint16_t len;

	mavlink_msg_rc_channels_override_pack(system_id,component_id,&msg,target_system,target_component,
		chan1_raw,chan2_raw,chan3_raw,chan4_raw,chan5_raw,chan6_raw,chan7_raw,chan8_raw);
	len = mavlink_msg_to_send_buffer(buf, &msg);
	BSP_USART_SendArray_LL( USART1,buf,sizeof(buf));
	//UART_Send_Str(buf,len);

	mavlink_msg_rc_channels_override_pack(system_id,component_id,&msg,target_system,target_component,
		0,chan2_raw,chan3_raw,chan4_raw,chan5_raw,chan6_raw,chan7_raw,chan8_raw);

	len = mavlink_msg_to_send_buffer(buf, &msg);
	//UART_Send_Str(buf,len);
	BSP_USART_SendArray_LL( USART1,buf,sizeof(buf));
}

//*****心跳信号*************************
void heartbeat_Mavlink(void)
{
	uint8_t system_id=255;
	uint8_t component_id=0;
	mavlink_message_t heart_msg;
	uint8_t type=0x06;
	uint8_t autopilot=0x08;
	uint8_t base_mode=0xc0;
	uint32_t custom_mode=0x0000;
	uint8_t system_status=0x04;

	uint8_t buf_head[MAVLINK_MAX_PACKET_LEN];
	uint16_t len;

	mavlink_msg_heartbeat_pack( system_id,component_id, &heart_msg,type, autopilot,base_mode,custom_mode,system_status);
	len = mavlink_msg_to_send_buffer(buf_head, &heart_msg);
	//UART_Send_Str(buf_head,len);
	BSP_USART_SendArray_LL( USART1,buf_head,sizeof(buf_head));
}

//读取工作模式
int RC_Read(void)
{
	if(CHANNEL_6_PULSE_WIDE>=PWM_Mode_N1 && CHANNEL_6_PULSE_WIDE<=PWM_Mode_N2)
	{

	  return 1;
	}
  else if(CHANNEL_6_PULSE_WIDE>=PWM_Mode_N2 && CHANNEL_6_PULSE_WIDE<=PWM_Mode_N3)
	{
	  return 2;
	}
	else if(CHANNEL_6_PULSE_WIDE>=PWM_Mode_N3 && CHANNEL_6_PULSE_WIDE<=PWM_Mode_N4)
	{
	  return 3;
	}
	else return 1;
}

//各通道回中

void Back_to_Center(void)
{
	Set_PWM_Thr(4500);
	Set_PWM_Pitch(4500);
	Set_PWM_Roll(4500);
	Set_PWM_Yaw(4500);
	Set_PWM_Mode(4500);
}
/* USER CODE END 4 */

/* MPU Configuration */

void MPU_Config(void)
{
  MPU_Region_InitTypeDef MPU_InitStruct = {0};

  /* Disables the MPU */
  HAL_MPU_Disable();

  /** Initializes and configures the Region and the memory to be protected
  */
  MPU_InitStruct.Enable = MPU_REGION_ENABLE;
  MPU_InitStruct.Number = MPU_REGION_NUMBER0;
  MPU_InitStruct.BaseAddress = 0x0;
  MPU_InitStruct.Size = MPU_REGION_SIZE_4GB;
  MPU_InitStruct.SubRegionDisable = 0x87;
  MPU_InitStruct.TypeExtField = MPU_TEX_LEVEL0;
  MPU_InitStruct.AccessPermission = MPU_REGION_NO_ACCESS;
  MPU_InitStruct.DisableExec = MPU_INSTRUCTION_ACCESS_DISABLE;
  MPU_InitStruct.IsShareable = MPU_ACCESS_SHAREABLE;
  MPU_InitStruct.IsCacheable = MPU_ACCESS_NOT_CACHEABLE;
  MPU_InitStruct.IsBufferable = MPU_ACCESS_NOT_BUFFERABLE;

  HAL_MPU_ConfigRegion(&MPU_InitStruct);
  /* Enables the MPU */
  HAL_MPU_Enable(MPU_PRIVILEGED_DEFAULT);

}

void Error_Handler(void)
{
  __disable_irq();
  while (1)
  {
  }
}
